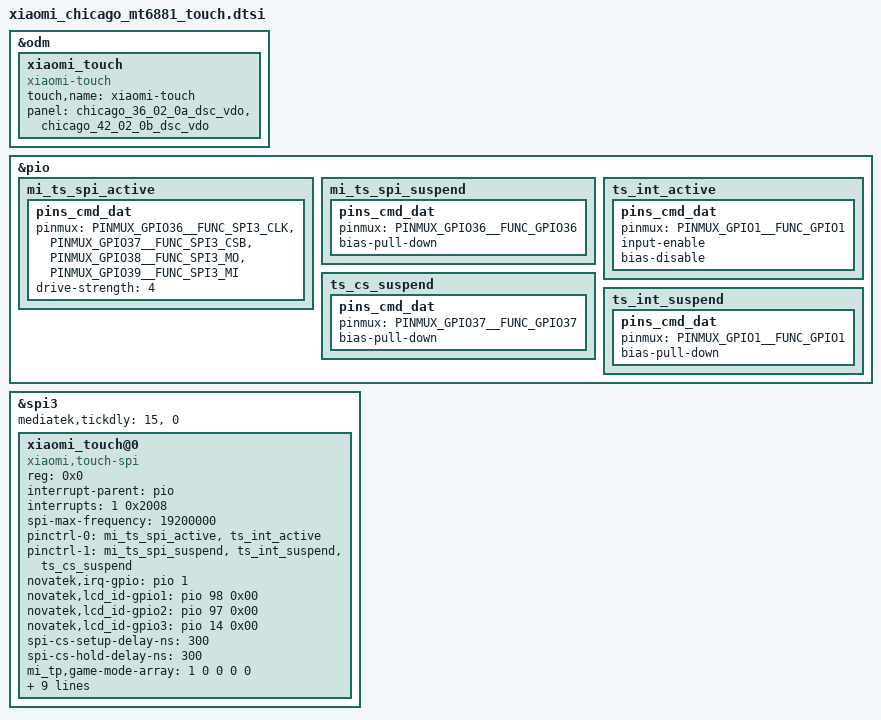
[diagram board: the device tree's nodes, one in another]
// SPDX-License-Identifier: (GPL-2.0 OR MIT)
/*
 * Copyright (C) 2020 MediaTek Inc.
 */

/* TOUCH start */
&odm {
	xiaomi_touch: xiaomi_touch {
		compatible = "xiaomi-touch";
		status = "ok";
		touch,name = "xiaomi-touch";
		panel = <&chicago_36_02_0a_dsc_vdo
		&chicago_42_02_0b_dsc_vdo>;
	};
};

&pio {
	mi_ts_spi_active: mi_ts_spi_active {
		pins_cmd_dat {
			pinmux = <PINMUX_GPIO36__FUNC_SPI3_CLK>,
					<PINMUX_GPIO37__FUNC_SPI3_CSB>,
					<PINMUX_GPIO38__FUNC_SPI3_MO>,
					<PINMUX_GPIO39__FUNC_SPI3_MI>;
			drive-strength = <4>;
		};
	};
	mi_ts_spi_suspend: mi_ts_spi_suspend {
		pins_cmd_dat {
			pinmux = <PINMUX_GPIO36__FUNC_GPIO36>;
			bias-pull-down;
		};
	};
	ts_int_active: ts_int_active {
		pins_cmd_dat {
			pinmux = <PINMUX_GPIO1__FUNC_GPIO1>;
			input-enable;
			bias-disable;
		};
	};
	ts_cs_suspend:ts_cs_suspend {
		pins_cmd_dat{
			pinmux = <PINMUX_GPIO37__FUNC_GPIO37>;
			bias-pull-down;
		};
	};
	ts_int_suspend: ts_int_suspend {
		pins_cmd_dat {
			pinmux = <PINMUX_GPIO1__FUNC_GPIO1>;
			bias-pull-down;
		};
	};
};

&spi3 {
	status = "ok";
	mediatek,tickdly = <15>, <0>;

	/* Novatek device tree node */
	xiaomi_touch@0 {
		compatible = "xiaomi,touch-spi";
		reg = <0x0>;
		status = "ok";
		interrupt-parent = <&pio>;
		interrupts = <1 0x2008>;
		spi-max-frequency = <19200000>;	//4800000,9600000,15000000,19200000
		pinctrl-names = "pmx_ts_active", "pmx_ts_suspend";
		pinctrl-0 = <&mi_ts_spi_active &ts_int_active>;
		pinctrl-1 = <&mi_ts_spi_suspend &ts_int_suspend &ts_cs_suspend>;

		/* novatek dtsi start */
		novatek,irq-gpio = <&pio 1 0x2008>;
		novatek,lcd_id-gpio1 = <&pio 98 0x00>;
		novatek,lcd_id-gpio2 = <&pio 97 0x00>;
		novatek,lcd_id-gpio3 = <&pio 14 0x00>;
		spi-cs-setup-delay-ns = <300>;
		spi-cs-hold-delay-ns = <300>;

		/* xiaomi touch default param */
		mi_tp,game-mode-array =
						<1 0 0 0 0>;  /* MAX MIN DEF SET GET */
		mi_tp,active-mode-array =
						<1 0 0 0 0>;  /* MAX MIN DEF SET GET */
		mi_tp,tolerance-array =
						<4 0 2 2 2>;  /* MAX MIN DEF SET GET */
		mi_tp,up-threshold-array =
						<4 0 3 3 3>;  /* MAX MIN DEF SET GET */
		mi_tp,aim-sensitivity-array =
						<4 0 2 2 2>;  /* MAX MIN DEF SET GET */
		mi_tp,tap-stability-array =
						<4 0 2 2 2>;  /* MAX MIN DEF SET GET */
		mi_tp,edge-filter-array =
						<3 0 2 2 2>;  /* MAX MIN DEF SET GET */
		mi_tp,panel-orien-array =
						<3 0 0 0 0>;  /* MAX MIN DEF SET GET */
		mi_tp,report-rate-array =
						<3 0 0 0 0>;  /* MAX MIN DEF SET GET */
		mi_tp,expert-mode-array =
						<3 1 1 1 1>;  /* MAX MIN DEF SET GET */
		/* novatek dtsi end */
	};
};

/* TOUCH end */
